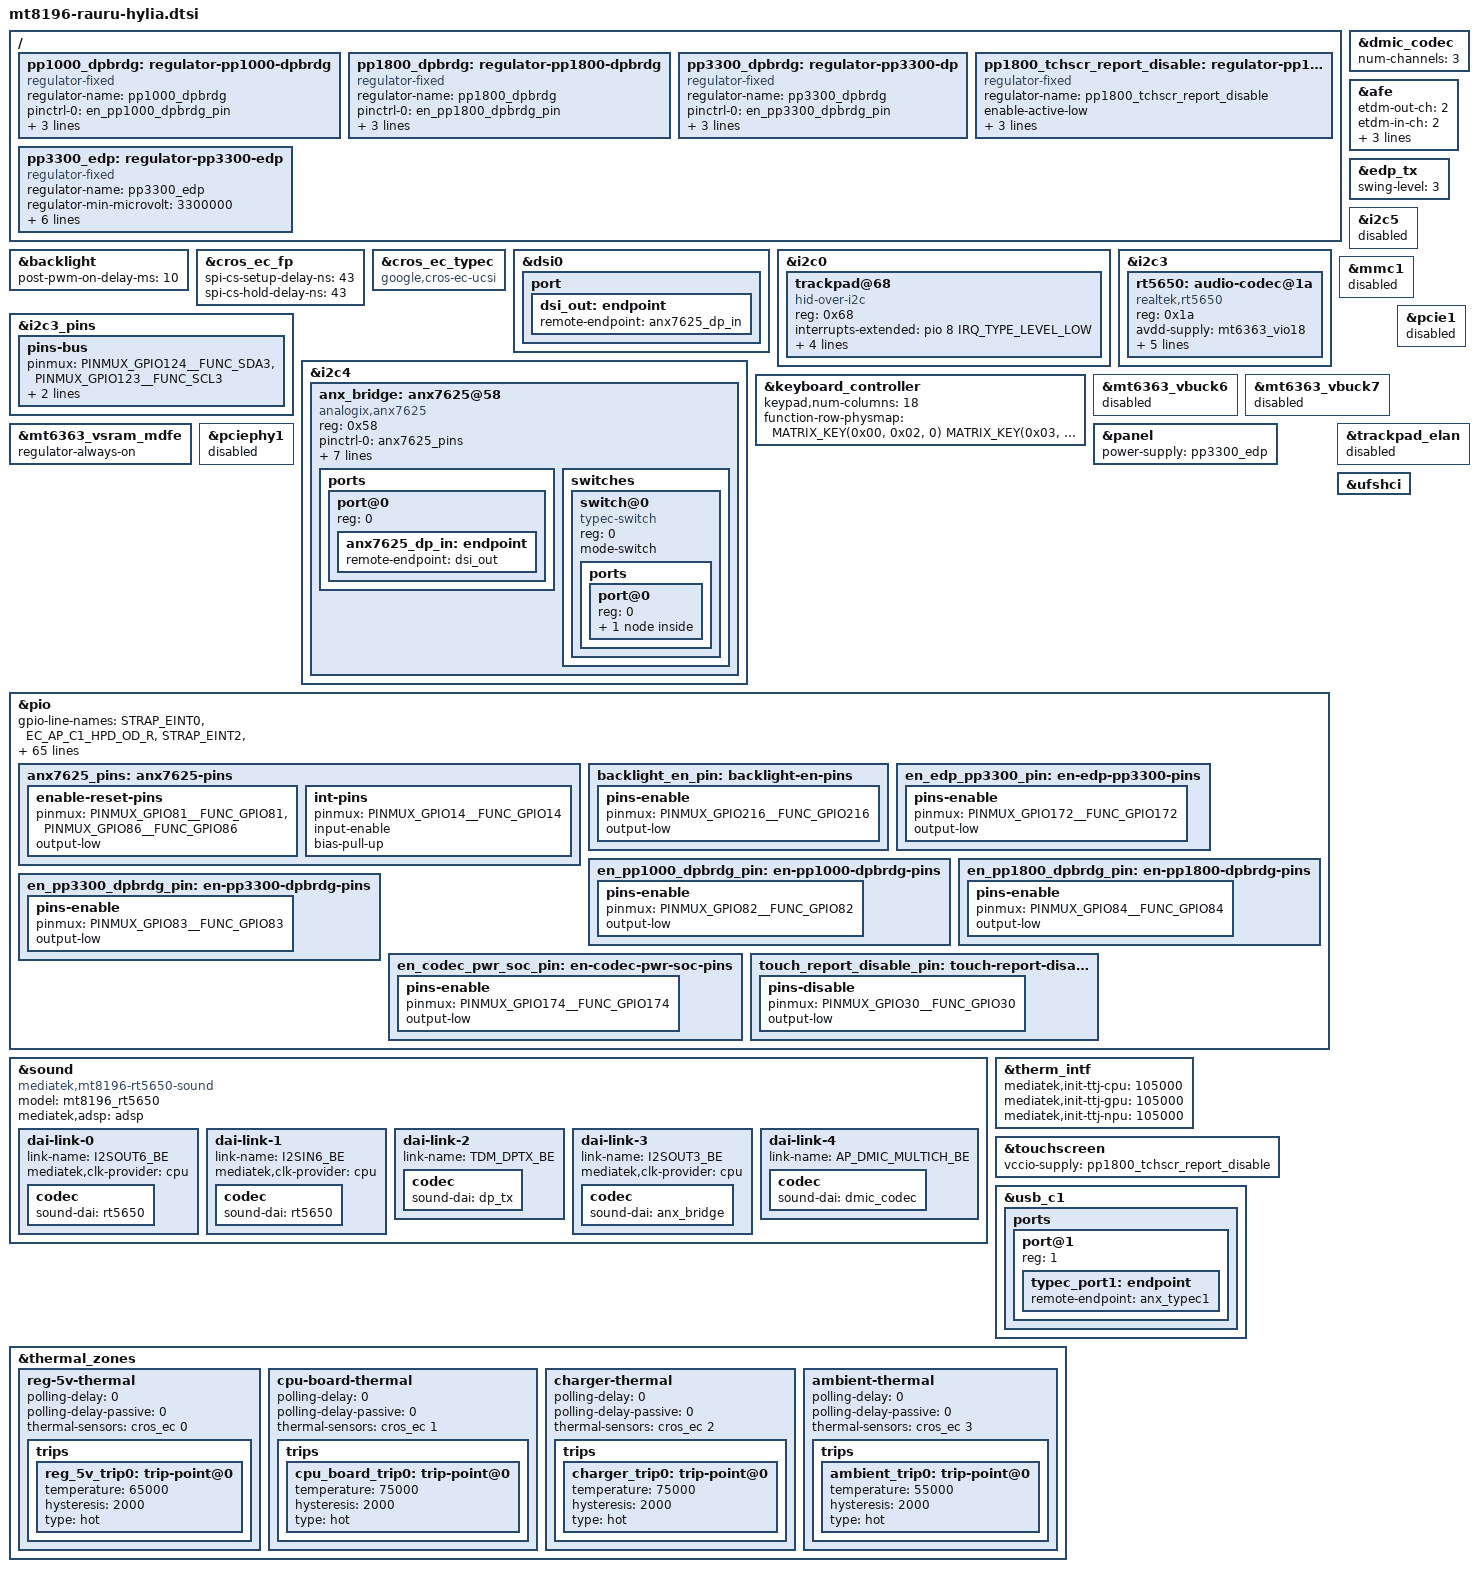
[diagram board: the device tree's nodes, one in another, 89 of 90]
// SPDX-License-Identifier: (GPL-2.0 OR MIT)
/*
 * Copyright 2025 Google LLC
 */

/dts-v1/;
#include "mt8196-rauru.dtsi"

/ {
	pp1000_dpbrdg: regulator-pp1000-dpbrdg {
		compatible = "regulator-fixed";
		regulator-name = "pp1000_dpbrdg";
		pinctrl-names = "default";
		pinctrl-0 = <&en_pp1000_dpbrdg_pin>;
		enable-active-high;
		//regulator-boot-on;
		gpio = <&pio 82 GPIO_ACTIVE_HIGH>;
		vin-supply = <&pp3300_z1>;
	};

	pp1800_dpbrdg: regulator-pp1800-dpbrdg {
		compatible = "regulator-fixed";
		regulator-name = "pp1800_dpbrdg";
		pinctrl-names = "default";
		pinctrl-0 = <&en_pp1800_dpbrdg_pin>;
		enable-active-high;
		//regulator-boot-on;
		gpio = <&pio 84 GPIO_ACTIVE_HIGH>;
		vin-supply = <&mt6363_vio18>;
	};

	pp3300_dpbrdg: regulator-pp3300-dp {
		compatible = "regulator-fixed";
		regulator-name = "pp3300_dpbrdg";
		pinctrl-names = "default";
		pinctrl-0 = <&en_pp3300_dpbrdg_pin>;
		enable-active-high;
		//regulator-boot-on;
		gpio = <&pio 83 GPIO_ACTIVE_HIGH>;
		vin-supply = <&pp3300_z1>;
	};

	pp1800_tchscr_report_disable: regulator-pp1800-tchscr-report-disable {
		compatible = "regulator-fixed";
		regulator-name = "pp1800_tchscr_report_disable";
		pinctrl-names = "default";
		enable-active-low;
		regulator-boot-on;
		pinctrl-0 = <&touch_report_disable_pin>;
		gpio = <&pio 30 GPIO_ACTIVE_LOW>;
	};

	pp3300_edp: regulator-pp3300-edp {
		compatible = "regulator-fixed";
		regulator-name = "pp3300_edp";
		regulator-min-microvolt = <3300000>;
		regulator-max-microvolt = <3300000>;
		enable-active-high;
		gpio = <&pio 172 GPIO_ACTIVE_HIGH>;
		pinctrl-names = "default";
		pinctrl-0 = <&en_edp_pp3300_pin>;
		vin-supply = <&pp3300_z1>;

		regulator-always-on;
	};
};

&dmic_codec {
	num-channels = <3>;
};

&afe {
	/* Only for ETDM in/out 4 */
	etdm-out-ch = <2>;
	etdm-in-ch = <2>;
	etdm-out-sync = <0>; /* 0: disable; 1: enable */
	etdm-in-sync = <0>; /* 0: disable; 1: enable */
	etdm-ip-mode = <0>; /* 0: One IP multi-channel 1: Multi-IP 2-channel */
	status = "okay";
};

&backlight {
	post-pwm-on-delay-ms = <10>;
};

&cros_ec_fp {
	spi-cs-setup-delay-ns = <43>;
	spi-cs-hold-delay-ns = <43>;
};

&cros_ec_typec {
	compatible = "google,cros-ec-ucsi";
};

&dsi0 {
	status = "okay";

	port {
		dsi_out: endpoint {
			remote-endpoint = <&anx7625_dp_in>;
		};
	};
};

&edp_tx {
	swing-level = <3>;
};

&i2c0 {
	/* carewe trackpad */
	trackpad@68 {
		compatible = "hid-over-i2c";
		reg = <0x68>;
		interrupts-extended = <&pio 8 IRQ_TYPE_LEVEL_LOW>;
		hid-descr-addr = <0x0020>;
		vdd-supply = <&mt6373_vcn33_2>;
		post-power-on-delay-ms = <50>;
		wakeup-source;
	};
};

&i2c3 {
	/delete-node/ audio-codec@1a;

	rt5650: audio-codec@1a {
		compatible = "realtek,rt5650";
		reg = <0x1a>;
		avdd-supply = <&mt6363_vio18>;
		pinctrl-names = "default";
		pinctrl-0 = <&en_codec_pwr_soc_pin>;
		cbj-sleeve-gpio = <&pio 174 GPIO_ACTIVE_HIGH>;
		interrupts-extended = <&pio 10 IRQ_TYPE_EDGE_BOTH>;
		#sound-dai-cells = <0>;
		realtek,dmic1-data-pin = <2>;
		realtek,jd-mode = <2>;
	};
};

&i2c3_pins {
	pins-bus {
		pinmux = <PINMUX_GPIO124__FUNC_SDA3>,
			 <PINMUX_GPIO123__FUNC_SCL3>;

		/delete-property/ bias-pull-up;
		bias-disable;
		drive-strength = <4>;
	};
};

&i2c4 {
	anx_bridge: anx7625@58 {
		compatible = "analogix,anx7625";
		reg = <0x58>;
		pinctrl-names = "default";
		pinctrl-0 = <&anx7625_pins>;
		enable-gpios = <&pio 81 GPIO_ACTIVE_HIGH>;
		reset-gpios = <&pio 86 GPIO_ACTIVE_HIGH>;
		interrupts-extended = <&pio 14 IRQ_TYPE_LEVEL_LOW>;
		vdd10-supply = <&pp1000_dpbrdg>;
		vdd18-supply = <&pp1800_dpbrdg>;
		vdd33-supply = <&pp3300_dpbrdg>;
		analogix,audio-enable;
		#address-cells = <1>;
		#size-cells = <0>;
		#sound-dai-cells = <0>;

		ports {
			#address-cells = <1>;
			#size-cells = <0>;

			port@0 {
				reg = <0>;

				anx7625_dp_in: endpoint {
					remote-endpoint = <&dsi_out>;
				};
			};
		};

		switches {
			#address-cells = <1>;
			#size-cells = <0>;
			switch@0 {
				compatible = "typec-switch";
				reg = <0>;
				mode-switch;

				ports {
					#address-cells = <1>;
					#size-cells = <0>;

					port@0 {
						reg = <0>;

						anx_typec1: endpoint {
							remote-endpoint = <&typec_port1>;
						};
					};
				};
			};
		};
	};
};

&i2c5 {
	status = "disabled";
};

&keyboard_controller {
	keypad,num-columns = <18>;

	function-row-physmap = <
		MATRIX_KEY(0x00, 0x02, 0)		/* T1 */
		MATRIX_KEY(0x03, 0x02, 0)		/* T2 */
		MATRIX_KEY(0x02, 0x02, 0)		/* T3 */
		MATRIX_KEY(0x01, 0x02, 0)		/* T4 */
		MATRIX_KEY(0x04, 0x04, 0)		/* T5 */
		MATRIX_KEY(0x02, 0x04, 0)		/* T6 */
		MATRIX_KEY(0x01, 0x04, 0)		/* T7 */
		MATRIX_KEY(0x02, 0x0b, 0)		/* T8 */
		MATRIX_KEY(0x01, 0x09, 0)		/* T9 */
		MATRIX_KEY(0x00, 0x04, 0)		/* T10 */
		MATRIX_KEY(0x00, 0x01, 0)		/* T11 */
		MATRIX_KEY(0x01, 0x05, 0)		/* T12 */
		MATRIX_KEY(0x03, 0x05, 0)		/* T13 */
		MATRIX_KEY(0x00, 0x0b, 0)		/* T14 */
	>;
};

&mmc1 {
	status = "disabled";
};

&mt6363_vbuck6 {
	status = "disabled";
};

&mt6363_vbuck7 {
	status = "disabled";
};

&mt6363_vsram_mdfe {
	regulator-always-on;
};

&panel {
	power-supply = <&pp3300_edp>;
};

&pcie1 {
	status = "disabled";
};

&pciephy1 {
	status = "disabled";
};

&pio {
	/* 271 lines */
	gpio-line-names =
		"STRAP_EINT0",			/* 0 */
		"EC_AP_C1_HPD_OD_R",
		"STRAP_EINT2",
		/*
		 * AP_FLASH_WP_L is crossystem ABI. Schematics
		 * call it AP_WP_ODL.
		 */
		"AP_FLASH_WP_L",
		"HPD_INT_AP_L",
		"LID_ACCEL_INT_SCP_L",
		"IMU_INT_SCP_L",
		"TCHSCR_INT_1V8_ODL",
		"TCHPAD_INT_ODL",
		"",
		"HP_INT_ODL",			/* 10 */
		"SD_CD_AP_ODL",
		"FP_AP_INT_1V8_S3_ODL",
		"EDP_HPD_1V8",
		"DPBRDG_INT_ODL",
		"",
		"STRAP_EINT16",
		"STRAP_EINT17",
		"GSC_AP_INT_ODL",
		"EC_AP_INT_ODL",
		"",		/* 20 */
		"",
		"",
		"DMIC1_CLK",
		"DMIC1_DATA",
		"",
		"FP_RST_1V8_S3_L",
		"AP_FP_FW_UP_STRAP",
		"AP_XHCI_INIT_DONE",
		"AP_EC_WARM_RST_REQ",
		"TCHSCR_REPORT_DISABLE",	/* 30 */
		"TCHSCR_RST_1V8_L",
		"EC_AP_DP_HPD_OD",
		"IO_JTAG_TRST_L",
		"IO_JTAG_TDI",
		"IO_JTAG_TDO",
		"IO_JTAG_TMS",
		"",
		"AP_SUSPEND_L",
		"I2S_HP_MCK",
		"I2S_HP_BCK",			/* 40 */
		"I2S_HP_LRCK",
		"I2S_HP_DI",
		"I2S_HP_DO",
		"",
		"",
		"",
		"",
		"",
		"",
		"",				/* 50 */
		"",
		"",
		"",
		"",
		"",
		"STRAP_AUD_DAT_MOSI0",
		"STRAP_AUD_DAT_MOSI1",
		"",
		"",
		"AP_KPCOL0",			/* 60 */
		"CPUM_PMIC_POC",
		"CPUB_PMIC_POC",
		"GPU_PMIC_POC",
		"",
		"",
		"AP_PMIC_WDTRST_L",
		"SRCLKENA0",
		"STRAP_SCP_VREQ_VAO",
		"SOC_RTC32K_1V8",
		"STRAP_FL_STROBE_EN",		/* 70 */
		"",
		"USB_EN",
		"STRAP_LVSYS_INT",
		"STRAP_FPM_IND",
		"SPMI_M_SCL",
		"SPMI_M_SDA",
		"SPMI_P_SCL",
		"SPMI_P_SDA",
		"",
		"",				/* 80 */
		"DPBRDG_PWREN",
		"EN_PP1000_DPBRDG",
		"EN_PP3300_DPBRDG",
		"EN_PP1800_DPBRDG",
		"",
		"DPBRDG_RST_L",
		"",
		"",
		"",
		"",				/* 90 */
		"SPI_AP_DO_BIOS_DI",
		"SPI_AP_DI_BIOS_DO",
		"",
		"",
		"",
		"",
		"",
		"",
		"AP_I2C_TCHPAD_SCL_1V8",
		"AP_I2C_TCHPAD_SDA_1V8",	/* 100 */
		"SPI_AP_CS_BIOS_L",
		"SPI_AP_CLK_BIOS",
		"BL_PWM_1V8",
		"AP_I2C_EUSB_SCL_1V8",
		"AP_I2C_EUSB_SDA_1V8",
		"",
		"",
		"",
		"",
		"SPI_AP_CLK_EC",		/* 110 */
		"SPI_AP_CS_EC_L",
		"SPI_AP_DO_EC_DI",
		"SPI_AP_DI_EC_DO",
		"",
		"",
		"",
		"",
		"SPI_AP_CLK_FP_1V8",
		"SPI_AP_CS_FP_1V8_L",
		"SPI_AP_DO_FP_DI_1V8",		/* 120 */
		"SPI_AP_DI_FP_DO_1V8",
		"",
		"AP_I2C_AUD_SCL_1V8",
		"AP_I2C_AUD_SDA_1V8",
		"",
		"",
		"",
		"",
		"",
		"",			/* 130 */
		"",
		"",
		"",
		"",
		"",
		"",
		"",
		"",
		"",
		"",				/* 140 */
		"",
		"",
		"",
		"",
		"",
		"",
		"",
		"",
		"",
		"",		/* 150 */
		"",
		"",
		"",
		"",
		"",
		"",
		"UART_AP_TX_FP_RX_1V8",
		"UART_FP_TX_AP_RX_1V8",
		"",
		"UART_AP_TX_GSC_DBG_RX",	/* 160 */
		"UART_GSC_DBG_TX_AP_RX",
		"UART_IO_TX_DBGCON_RX",
		"UART_DBGCON_TX_IO_RX",
		"SCP_I2C_SENSOR_SCL_1V8",
		"SCP_I2C_SENSOR_SDA_1V8",
		"SCP2_I2C_SENSOR_SCL_1V8_R",
		"SCP2_I2C_SENSOR_SDA_1V8_R",
		"SPI_AP_CLK_TCHSCR",
		"SPI_AP_CS_TCHSCR_L",
		"SPI_AP_DO_TCHSCR_DI",		/* 170 */
		"SPI_AP_DI_TCHSCR_DO",
		"EN_PP3300_EDP_X",
		"EN_PWR_FP",
		"CODEC_PWR_SOC_EN",
		"",
		"",
		"",
		"DMIC0_CLK",
		"DMIC0_DATA",
		"",				/* 180 */
		"",
		"",
		"",
		"",
		"",
		"",
		"",
		"AP_I2C_TCHSCR_SCL_1V8",
		"AP_I2C_TCHSCR_SDA_1V8",
		"AP_I2C_DPBRDG_SCL_1V8",		/* 190 */
		"AP_I2C_DPBRDG_SDA_1V8",
		"",
		"",
		"",
		"",
		"",
		"",
		"",
		"",
		"AP_I2C_TPM_SCL_1V8",		/* 200 */
		"AP_I2C_TPM_SDA_1V8",
		"",
		"",
		"",
		"",
		"",
		"",
		"",
		"",
		"",				/* 210 */
		"",
		"",
		"",
		"",
		"",
		"EDP_BL_EN_1V8",
		"",
		"",
		"AP_JTAG_TRST_L",
		"AP_JTAG_TCK",			/* 220 */
		"AP_JTAG_TMS",
		"AP_JTAG_TDO",
		"AP_JTAG_TDI",
		"",
		"",
		"I2SIN3_BLCK",
		"I2SIN3_LRCK",
		"",
		"I2SIN3_DO",
		"",				/* 230 */
		"",
		"",
		"",
		"",
		"",
		"",
		"",
		"",
		"",
		"",				/* 240 */
		"PCIE_WLAN_RST_1V2_L",
		"PCIE_WLAN_WAKE_OBFF_1V2_ODL",
		"PCIE_WLAN_CLKREQ_1V2_ODL",
		"",
		"",
		"",
		"",
		"BT_KILL_1V2_L",
		"WIFI_KILL_1V2_L",
		"",				/* 250 */
		"",
		"",
		"",
		"",
		"",
		"",
		"",
		"",
		"",
		"",				/* 260 */
		"",
		"",
		"",
		"",
		"",
		"",
		"",
		"",
		"",
		"";				/* 270 */

	anx7625_pins: anx7625-pins {
		enable-reset-pins {
			pinmux = <PINMUX_GPIO81__FUNC_GPIO81>,
				 <PINMUX_GPIO86__FUNC_GPIO86>;
			output-low;
		};

		int-pins {
			pinmux = <PINMUX_GPIO14__FUNC_GPIO14>;
			input-enable;
			bias-pull-up;
		};
	};

	backlight_en_pin: backlight-en-pins {
		pins-enable {
			pinmux = <PINMUX_GPIO216__FUNC_GPIO216>;
			output-low;
		};
	};

	en_edp_pp3300_pin: en-edp-pp3300-pins {
		pins-enable {
			pinmux = <PINMUX_GPIO172__FUNC_GPIO172>;
			output-low;
		};
	};

	en_pp1000_dpbrdg_pin: en-pp1000-dpbrdg-pins {
		pins-enable {
			pinmux = <PINMUX_GPIO82__FUNC_GPIO82>;
			output-low;
		};
	};

	en_pp1800_dpbrdg_pin: en-pp1800-dpbrdg-pins {
		pins-enable {
			pinmux = <PINMUX_GPIO84__FUNC_GPIO84>;
			output-low;
		};
	};

	en_pp3300_dpbrdg_pin: en-pp3300-dpbrdg-pins {
		pins-enable {
			pinmux = <PINMUX_GPIO83__FUNC_GPIO83>;
			output-low;
		};
	};

	en_codec_pwr_soc_pin: en-codec-pwr-soc-pins {
		pins-enable {
			pinmux = <PINMUX_GPIO174__FUNC_GPIO174>;
			output-low;
		};
	};

	touch_report_disable_pin: touch-report-disable-pins {
		pins-disable {
			pinmux = <PINMUX_GPIO30__FUNC_GPIO30>;
			output-low;
		};
	};
};

&sound {
	compatible = "mediatek,mt8196-rt5650-sound";
	model = "mt8196_rt5650";
	mediatek,adsp = <&adsp>;
	status = "okay";

	dai-link-0 {
		link-name = "I2SOUT6_BE";
		mediatek,clk-provider = "cpu";

		codec {
			sound-dai = <&rt5650>;
		};
	};

	dai-link-1 {
		link-name = "I2SIN6_BE";
		mediatek,clk-provider = "cpu";

		codec {
			sound-dai = <&rt5650>;
		};
	};

	dai-link-2 {
		link-name = "TDM_DPTX_BE";

		codec {
			sound-dai = <&dp_tx>;
		};
	};

	dai-link-3 {
		link-name = "I2SOUT3_BE";
		mediatek,clk-provider = "cpu";

		codec {
			sound-dai = <&anx_bridge>;
		};
	};

	dai-link-4 {
		link-name = "AP_DMIC_MULTICH_BE";

		codec {
			sound-dai = <&dmic_codec>;
		};
	};
};

&therm_intf {
	mediatek,init-ttj-cpu = <105000>;
	mediatek,init-ttj-gpu = <105000>;
	mediatek,init-ttj-npu = <105000>;
};

&touchscreen {
	vccio-supply = <&pp1800_tchscr_report_disable>;
};

&trackpad_elan {
	status = "disabled";
};

&ufshci {
	/delete-property/ mediatek,ufs-rtff-mtcmos;
};

&usb_c1 {
	ports {
		#address-cells = <1>;
		#size-cells = <0>;

		port@1 {
			reg = <1>;

			typec_port1: endpoint {
				remote-endpoint = <&anx_typec1>;
			};
		};
	};
};

&thermal_zones {
	reg-5v-thermal {
		polling-delay = <0>;
		polling-delay-passive = <0>;
		thermal-sensors = <&cros_ec 0>;

		trips {
			reg_5v_trip0: trip-point@0 {
				temperature = <65000>;
				hysteresis = <2000>;
				type = "hot";
			};
		};
	};

	cpu-board-thermal {
		polling-delay = <0>;
		polling-delay-passive = <0>;
		thermal-sensors = <&cros_ec 1>;

		trips {
			cpu_board_trip0: trip-point@0 {
				temperature = <75000>;
				hysteresis = <2000>;
				type = "hot";
			};
		};
	};

	charger-thermal {
		polling-delay = <0>;
		polling-delay-passive = <0>;
		thermal-sensors = <&cros_ec 2>;

		trips {
			charger_trip0: trip-point@0 {
				temperature = <75000>;
				hysteresis = <2000>;
				type = "hot";
			};
		};
	};

	ambient-thermal {
		polling-delay = <0>;
		polling-delay-passive = <0>;
		thermal-sensors = <&cros_ec 3>;

		trips {
			ambient_trip0: trip-point@0 {
				temperature = <55000>;
				hysteresis = <2000>;
				type = "hot";
			};
		};
	};
};
